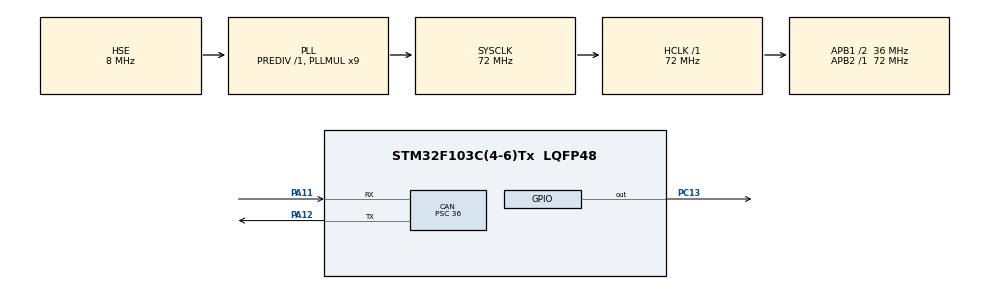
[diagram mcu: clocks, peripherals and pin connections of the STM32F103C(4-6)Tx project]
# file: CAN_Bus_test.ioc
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CAN.BS1=CAN_BS1_2TQ
CAN.BS2=CAN_BS2_1TQ
CAN.CalculateBaudRate=250000
CAN.CalculateTimeBit=4000
CAN.CalculateTimeQuantum=1000.0
CAN.Mode=CAN_MODE_NORMAL
CAN.Prescaler=36
Mcu.Family=STM32F1
Mcu.Name=STM32F103C(4-6)Tx
Mcu.Package=LQFP48
NVIC.CAN1_RX1_IRQn=true\:0\:0\:false\:false\:true\:true\:true\:true
NVIC.PriorityGroup=NVIC_PRIORITYGROUP_4
NVIC.USB_LP_CAN1_RX0_IRQn=true\:0\:0\:false\:false\:true\:true\:true\:true
PA11.GPIO_PuPd=GPIO_NOPULL
PA11.Mode=CAN_Activate
PA11.Signal=CAN_RX
PA12.Mode=CAN_Activate
PA12.Signal=CAN_TX
PA13.Mode=Serial_Wire
PA13.Signal=SYS_JTMS-SWDIO
PA14.Mode=Serial_Wire
PA14.Signal=SYS_JTCK-SWCLK
PC13-TAMPER-RTC.GPIO_ModeDefaultOutputPP=GPIO_MODE_OUTPUT_PP
PC13-TAMPER-RTC.GPIO_PuPd=GPIO_PULLUP
PC13-TAMPER-RTC.GPIO_Speed=GPIO_SPEED_FREQ_MEDIUM
PC13-TAMPER-RTC.PinState=GPIO_PIN_SET
PC13-TAMPER-RTC.Signal=GPIO_Output
PD0-OSC_IN.Mode=HSE-External-Oscillator
PD0-OSC_IN.Signal=RCC_OSC_IN
PD1-OSC_OUT.Mode=HSE-External-Oscillator
PD1-OSC_OUT.Signal=RCC_OSC_OUT
ProjectManager.HeapSize=0x200
ProjectManager.StackSize=0x400
ProjectManager.TargetToolchain=STM32CubeIDE
RCC.ADCPresc=RCC_ADCPCLK2_DIV6
RCC.AHBFreq_Value=72000000
RCC.APB1CLKDivider=RCC_HCLK_DIV2
RCC.APB1Freq_Value=36000000
RCC.APB1TimFreq_Value=72000000
RCC.APB2Freq_Value=72000000
RCC.APB2TimFreq_Value=72000000
RCC.HCLKFreq_Value=72000000
RCC.PLLMUL=RCC_PLL_MUL9
RCC.PLLSourceVirtual=RCC_PLLSOURCE_HSE
RCC.SYSCLKFreq_VALUE=72000000
RCC.SYSCLKSource=RCC_SYSCLKSOURCE_PLLCLK
RCC.USBFreq_Value=72000000
board=custom

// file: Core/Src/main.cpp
/* USER CODE BEGIN Header */
/**
  ******************************************************************************
  * @file           : main.c
  * @brief          : Main program body
  ******************************************************************************
  * @attention
  *
  * Copyright (c) 2024 STMicroelectronics.
  * All rights reserved.
  *
  * This software is licensed under terms that can be found in the LICENSE file
  * in the root directory of this software component.
  * If no LICENSE file comes with this software, it is provided AS-IS.
  *
  ******************************************************************************
  */
/* USER CODE END Header */
#include <main.hpp>
#include "CAN_Bus.hpp"

CAN_HandleTypeDef hcan;

/* USER CODE BEGIN PV */
CAN_RxHeaderTypeDef RxHeader;  // CAN transmit header
uint8_t RxData[8];
uint32_t can_id;

typedef struct {
    uint8_t error_warning_flag;
    uint8_t error_passive_flag;
    uint8_t bus_off_flag;
    uint8_t stuff_error;
    uint8_t form_error;
    uint8_t acknowledgment_error;
    uint8_t bit_recessive_error;
    uint8_t bit_dominant_error;
    uint8_t crc_error;
} CAN_ErrorFlags;
/* USER CODE END PV */

void SystemClock_Config(void);
static void MX_GPIO_Init(void);
static void MX_CAN_Init(void);

/* USER CODE BEGIN 0 */
void HAL_CAN_RxFifo0MsgPendingCallback(CAN_HandleTypeDef *hcan){
	HAL_CAN_GetRxMessage(hcan, CAN_RX_FIFO0, &RxHeader, RxData);
	HAL_GPIO_TogglePin(GPIOC, GPIO_PIN_13);

}

void check_CAN_errors(CAN_HandleTypeDef *hcan, CAN_ErrorFlags *error_flags) {
    uint32_t error = HAL_CAN_GetError(hcan);

    // Reset all error flags
    error_flags->error_warning_flag = 0;
    error_flags->error_passive_flag = 0;
    error_flags->bus_off_flag = 0;
    error_flags->stuff_error = 0;
    error_flags->form_error = 0;
    error_flags->acknowledgment_error = 0;
    error_flags->bit_recessive_error = 0;
    error_flags->bit_dominant_error = 0;
    error_flags->crc_error = 0;

    if (error != HAL_CAN_ERROR_NONE) {
        if (error & HAL_CAN_ERROR_EWG) {
            error_flags->error_warning_flag = 1;
        }
        if (error & HAL_CAN_ERROR_EPV) {
            error_flags->error_passive_flag = 1;
        }
        if (error & HAL_CAN_ERROR_BOF) {
            error_flags->bus_off_flag = 1;
        }
        if (error & HAL_CAN_ERROR_STF) {
            error_flags->stuff_error = 1;
        }
        if (error & HAL_CAN_ERROR_FOR) {
            error_flags->form_error = 1;
        }
        if (error & HAL_CAN_ERROR_ACK) {
            error_flags->acknowledgment_error = 1;
        }
        if (error & HAL_CAN_ERROR_BR) {
            error_flags->bit_recessive_error = 1;
        }
        if (error & HAL_CAN_ERROR_BD) {
            error_flags->bit_dominant_error = 1;
        }
        if (error & HAL_CAN_ERROR_CRC) {
            error_flags->crc_error = 1;
        }
    }
}
/* USER CODE END 0 */

int main(void)
{

  /* USER CODE BEGIN 1 */
	CANBus canBus;
	CAN_ErrorFlags error_flags;
  /* USER CODE END 1 */

  /* MCU Configuration--------------------------------------------------------*/

  /* Reset of all peripherals, Initializes the Flash interface and the Systick. */
  HAL_Init();

  /* Configure the system clock */
  SystemClock_Config();

  /* Initialize all configured peripherals */
  MX_GPIO_Init();
  MX_CAN_Init();
  /* USER CODE BEGIN 2 */

  uint8_t trump[8] = {0x01, 0x02, 0x03, 0x04, 0x05, 0x06, 0x07, 0x08}; // Example data

  canBus.start(&hcan, CAN_ID_STD);
//  canBus.error(&hcan, 2047);
//  canBus.error(&hcan, 0x38b);
  /* USER CODE END 2 */

  /* Infinite loop */
  while (1)
  {
	canBus.transmit(&hcan, trump, 446);
	HAL_Delay(300);
  }
}

void SystemClock_Config(void)
{
  RCC_OscInitTypeDef RCC_OscInitStruct = {0};
  RCC_ClkInitTypeDef RCC_ClkInitStruct = {0};

  /** Initializes the RCC Oscillators according to the specified parameters
  * in the RCC_OscInitTypeDef structure.
  */
  RCC_OscInitStruct.OscillatorType = RCC_OSCILLATORTYPE_HSE;
  RCC_OscInitStruct.HSEState = RCC_HSE_ON;
  RCC_OscInitStruct.HSEPredivValue = RCC_HSE_PREDIV_DIV1;
  RCC_OscInitStruct.HSIState = RCC_HSI_ON;
  RCC_OscInitStruct.PLL.PLLState = RCC_PLL_ON;
  RCC_OscInitStruct.PLL.PLLSource = RCC_PLLSOURCE_HSE;
  RCC_OscInitStruct.PLL.PLLMUL = RCC_PLL_MUL9;
  if (HAL_RCC_OscConfig(&RCC_OscInitStruct) != HAL_OK)
  {
    Error_Handler();
  }

  /** Initializes the CPU, AHB and APB buses clocks
  */
  RCC_ClkInitStruct.ClockType = RCC_CLOCKTYPE_HCLK|RCC_CLOCKTYPE_SYSCLK
                              |RCC_CLOCKTYPE_PCLK1|RCC_CLOCKTYPE_PCLK2;
  RCC_ClkInitStruct.SYSCLKSource = RCC_SYSCLKSOURCE_PLLCLK;
  RCC_ClkInitStruct.AHBCLKDivider = RCC_SYSCLK_DIV1;
  RCC_ClkInitStruct.APB1CLKDivider = RCC_HCLK_DIV2;
  RCC_ClkInitStruct.APB2CLKDivider = RCC_HCLK_DIV1;

  if (HAL_RCC_ClockConfig(&RCC_ClkInitStruct, FLASH_LATENCY_2) != HAL_OK)
  {
    Error_Handler();
  }
}

static void MX_CAN_Init(void)
{

  hcan.Instance = CAN1;
  hcan.Init.Prescaler = 36;
  hcan.Init.Mode = CAN_MODE_LOOPBACK; // Canbus normal mode = CAN_MODE_NORMAL, canbus loopback mode = CAN_MODE_LOOPBACK
  hcan.Init.SyncJumpWidth = CAN_SJW_1TQ;
  hcan.Init.TimeSeg1 = CAN_BS1_2TQ;
  hcan.Init.TimeSeg2 = CAN_BS2_1TQ;
  hcan.Init.TimeTriggeredMode = DISABLE;
  hcan.Init.AutoBusOff = DISABLE;
  hcan.Init.AutoWakeUp = DISABLE;
  hcan.Init.AutoRetransmission = DISABLE;
  hcan.Init.ReceiveFifoLocked = DISABLE;
  hcan.Init.TransmitFifoPriority = DISABLE;
  if (HAL_CAN_Init(&hcan) != HAL_OK)
  {
    Error_Handler();
  }
  /* USER CODE BEGIN CAN_Init 2 */
  CANBus canBus;

  canBus.configureFilter(&hcan, 0b00100010000, 0b00110110000, 10, 0);
  /* USER CODE END CAN_Init 2 */

}

static void MX_GPIO_Init(void)
{
	GPIO_InitTypeDef GPIO_InitStruct = { 0 };

	/* GPIO Ports Clock Enable */
	__HAL_RCC_GPIOC_CLK_ENABLE();
	__HAL_RCC_GPIOD_CLK_ENABLE();
	__HAL_RCC_GPIOA_CLK_ENABLE();

	/*Configure GPIO pin Output Level */
	HAL_GPIO_WritePin(GPIOC, GPIO_PIN_13, GPIO_PIN_SET);

	/*Configure GPIO pin : PC13 */
	GPIO_InitStruct.Pin = GPIO_PIN_13;
	GPIO_InitStruct.Mode = GPIO_MODE_OUTPUT_PP;
	GPIO_InitStruct.Pull = GPIO_PULLUP;
	GPIO_InitStruct.Speed = GPIO_SPEED_FREQ_MEDIUM;
	HAL_GPIO_Init(GPIOC, &GPIO_InitStruct);

}

void Error_Handler(void)
{
  __disable_irq();
  while (1)
  {
  }
}
